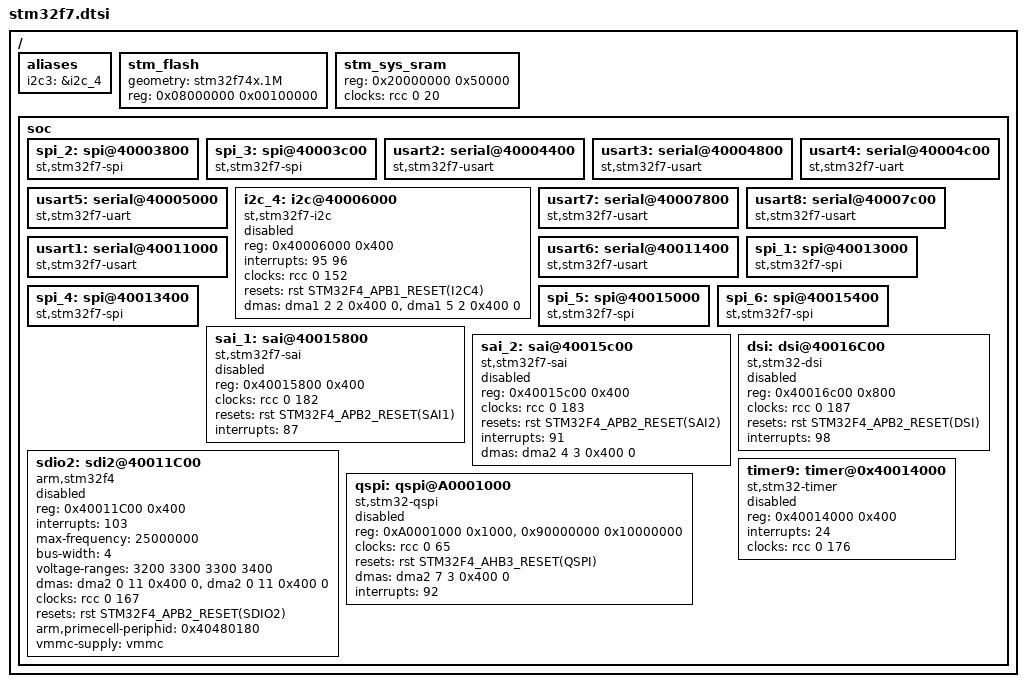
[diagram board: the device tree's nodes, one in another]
/*
 * Copyright 2016
 * Yuri Tikhonov, EmCraft Systems, <yur@emcraft.com>
 *
 * This file is dual-licensed: you can use it either under the terms
 * of the GPL or the X11 license, at your option. Note that this dual
 * licensing only applies to this file, and not this project as a
 * whole.
 *
 *  a) This file is free software; you can redistribute it and/or
 *     modify it under the terms of the GNU General Public License as
 *     published by the Free Software Foundation; either version 2 of the
 *     License, or (at your option) any later version.
 *
 *     This file is distributed in the hope that it will be useful,
 *     but WITHOUT ANY WARRANTY; without even the implied warranty of
 *     MERCHANTABILITY or FITNESS FOR A PARTICULAR PURPOSE.  See the
 *     GNU General Public License for more details.
 *
 *     You should have received a copy of the GNU General Public
 *     License along with this file; if not, write to the Free
 *     Software Foundation, Inc., 51 Franklin St, Fifth Floor, Boston,
 *     MA 02110-1301 USA
 *
 * Or, alternatively,
 *
 *  b) Permission is hereby granted, free of charge, to any person
 *     obtaining a copy of this software and associated documentation
 *     files (the "Software"), to deal in the Software without
 *     restriction, including without limitation the rights to use,
 *     copy, modify, merge, publish, distribute, sublicense, and/or
 *     sell copies of the Software, and to permit persons to whom the
 *     Software is furnished to do so, subject to the following
 *     conditions:
 *
 *     The above copyright notice and this permission notice shall be
 *     included in all copies or substantial portions of the Software.
 *
 *     THE SOFTWARE IS PROVIDED "AS IS", WITHOUT WARRANTY OF ANY KIND,
 *     EXPRESS OR IMPLIED, INCLUDING BUT NOT LIMITED TO THE WARRANTIES
 *     OF MERCHANTABILITY, FITNESS FOR A PARTICULAR PURPOSE AND
 *     NONINFRINGEMENT. IN NO EVENT SHALL THE AUTHORS OR COPYRIGHT
 *     HOLDERS BE LIABLE FOR ANY CLAIM, DAMAGES OR OTHER LIABILITY,
 *     WHETHER IN AN ACTION OF CONTRACT, TORT OR OTHERWISE, ARISING
 *     FROM, OUT OF OR IN CONNECTION WITH THE SOFTWARE OR THE USE OR
 *     OTHER DEALINGS IN THE SOFTWARE.
 */

#include "stm32.dtsi"

/ {
	aliases {
		i2c3 = &i2c_4;
	};

	stm_flash {
		geometry = "stm32f74x.1M";
		reg = <0x08000000 0x00100000>;
	};

	stm_sys_sram {
		reg = <0x20000000 0x50000>;
		clocks = <&rcc 0 20>;
	};

	soc {
		spi_2: spi@40003800 {
			compatible = "st,stm32f7-spi";
		};

		spi_3: spi@40003c00 {
			compatible = "st,stm32f7-spi";
		};

		usart2: serial@40004400 {
			compatible = "st,stm32f7-usart", "st,stm32f7-uart";
		};

		usart3: serial@40004800 {
			compatible = "st,stm32f7-usart", "st,stm32f7-uart";
		};

		usart4: serial@40004c00 {
			compatible = "st,stm32f7-uart";
		};

		usart5: serial@40005000 {
			compatible = "st,stm32f7-uart";
		};


		i2c_4: i2c@40006000 {
			compatible = "st,stm32f7-i2c";
			reg = <0x40006000 0x400>;
			interrupts = <95 96>;
			clocks = <&rcc 0 152>;
			resets = <&rst STM32F4_APB1_RESET(I2C4)>;
			dmas = <&dma1 2 2 0x400 0>, <&dma1 5 2 0x400 0>;
			dma-names = "rx", "tx";
			status = "disabled";
		};

		usart7: serial@40007800 {
			compatible = "st,stm32f7-usart", "st,stm32f7-uart";
		};

		usart8: serial@40007c00 {
			compatible = "st,stm32f7-usart", "st,stm32f7-uart";
		};

		usart1: serial@40011000 {
			compatible = "st,stm32f7-usart", "st,stm32f7-uart";
		};

		usart6: serial@40011400 {
			compatible = "st,stm32f7-usart", "st,stm32f7-uart";
		};

		spi_1: spi@40013000 {
			compatible = "st,stm32f7-spi";
		};

		spi_4: spi@40013400 {
			compatible = "st,stm32f7-spi";
		};

		spi_5: spi@40015000 {
			compatible = "st,stm32f7-spi";
		};

		spi_6: spi@40015400 {
			compatible = "st,stm32f7-spi";
		};

		sai_1: sai@40015800 {
			compatible = "st,stm32f7-sai";
			reg = <0x40015800 0x400>;
			clocks = <&rcc 0 182>;
			resets = <&rst STM32F4_APB2_RESET(SAI1)>;
			interrupts = <87>;
			status = "disabled";
		};

		sai_2: sai@40015c00 {
			compatible = "st,stm32f7-sai";
			reg = <0x40015c00 0x400>;
			clocks = <&rcc 0 183>;
			resets = <&rst STM32F4_APB2_RESET(SAI2)>;
			interrupts = <91>;
			dmas = <&dma2 4 3 0x400 0>;
			dma-names = "tx";
			status = "disabled";
		};

		dsi: dsi@40016C00 {
			compatible = "st,stm32-dsi";
			reg = <0x40016c00 0x800>;
			clocks = <&rcc 0 187>;
			resets = <&rst STM32F4_APB2_RESET(DSI)>;
			interrupts = <98>;
			status = "disabled";
		};

		sdio2: sdi2@40011C00 {
			compatible = "arm,stm32f4", "arm,primecell";
			reg = <0x40011C00 0x400>;
			interrupts = <103>;
			max-frequency = <25000000>;
			bus-width = <4>;
			voltage-ranges = <3200 3300 3300 3400>;
			/* Use the same DMA both for rx and tx */
			dmas = <&dma2 0 11 0x400 0>, <&dma2 0 11 0x400 0>;
			dma-names = "rx", "tx";
			clocks = <&rcc 0 167>;
			clock-names = "apb_pclk";
			resets = <&rst STM32F4_APB2_RESET(SDIO2)>;
			arm,primecell-periphid = <0x40480180>;
			vmmc-supply = <&vmmc>;
			status = "disabled";
		};

		qspi: qspi@A0001000 {
			compatible = "st,stm32-qspi";
			reg = <0xA0001000 0x1000>, <0x90000000 0x10000000>;
			clocks = <&rcc 0 65>;
			resets = <&rst STM32F4_AHB3_RESET(QSPI)>;
			dmas = <&dma2 7 3 0x400 0>;
			dma-names = "tx";
			interrupts = <92>;
			status = "disabled";
			#address-cells = <1>;
			#size-cells = <1>;
		};

		timer9: timer@0x40014000 {
			compatible = "st,stm32-timer";
			reg = <0x40014000 0x400>;
			interrupts = <24>;
			clocks = <&rcc 0 176>;
			status = "disabled";
		};
	};
};
